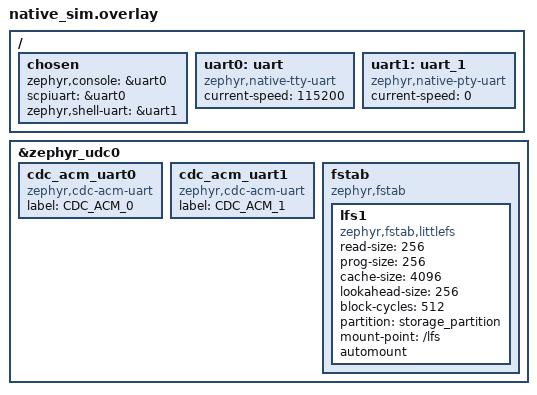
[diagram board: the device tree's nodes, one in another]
/*
 * Copyright (c) 2019 Jan Van Winkel (jan.van_winkel@dxplore.eu)
 *
 * SPDX-License-Identifier: Apache-2.0
 */

/ {
	chosen {
		zephyr,console = &uart0;
		scpiuart = &uart0;
		zephyr,shell-uart = &uart1;
		//zephyr,uart-mcumgr = &uart0;
		//zephyr,shell-uart = &cdc_acm_uart0;
		//zephyr,console = &cdc_acm_uart1;
		//scpiuart = &cdc_acm_uart1;
	};

	uart0: uart {
		status = "okay";
		compatible = "zephyr,native-tty-uart";
		/* Dummy current-speed entry to comply with serial
		 * DTS binding
		 */
		current-speed = <115200>;
	};

	uart1: uart_1 {
		status = "okay";
		compatible = "zephyr,native-pty-uart";
		/* Dummy current-speed entry to comply with serial
		 * DTS binding
		 */
		current-speed = <0>;
	};
};


&zephyr_udc0 {
	cdc_acm_uart0: cdc_acm_uart0 {
		compatible = "zephyr,cdc-acm-uart";
		label = "CDC_ACM_0";
	};
	cdc_acm_uart1: cdc_acm_uart1 {
		compatible = "zephyr,cdc-acm-uart";
		label = "CDC_ACM_1";
	};
	/*
	cdc_acm_uart2: cdc_acm_uart2 {
		compatible = "zephyr,cdc-acm-uart";
		label = "CDC_ACM_2";
	};
	*/



	fstab {
		compatible = "zephyr,fstab";
		lfs1: lfs1 {
			compatible = "zephyr,fstab,littlefs";
			read-size = <256>;
			prog-size = <256>;
			cache-size = <4096>;
			lookahead-size = <256>;
			block-cycles = <512>;
			partition = <&storage_partition>;
			mount-point = "/lfs";
			automount;
		};
	};

};
